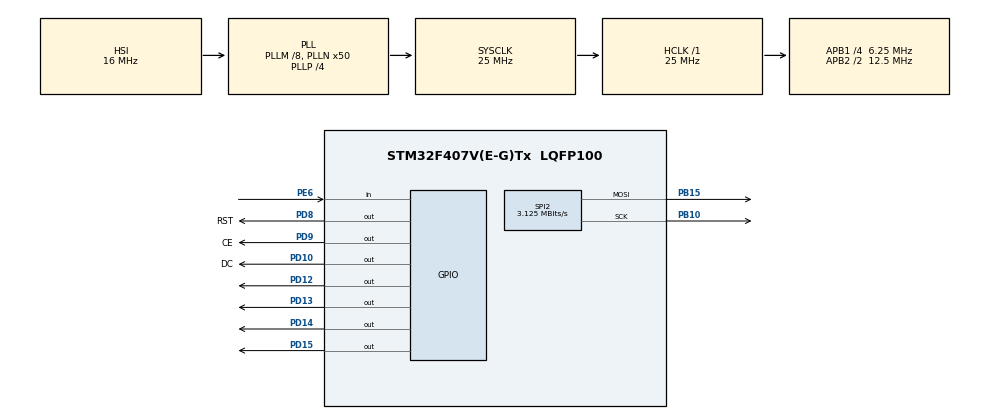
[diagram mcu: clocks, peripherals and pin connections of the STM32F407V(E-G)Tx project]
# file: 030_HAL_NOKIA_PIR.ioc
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Dma.Request0=SPI2_TX
Dma.SPI2_TX.0.Direction=DMA_MEMORY_TO_PERIPH
Dma.SPI2_TX.0.FIFOMode=DMA_FIFOMODE_DISABLE
Dma.SPI2_TX.0.Instance=DMA1_Stream4
Dma.SPI2_TX.0.MemDataAlignment=DMA_MDATAALIGN_BYTE
Dma.SPI2_TX.0.MemInc=DMA_MINC_ENABLE
Dma.SPI2_TX.0.Mode=DMA_CIRCULAR
Dma.SPI2_TX.0.PeriphDataAlignment=DMA_PDATAALIGN_BYTE
Dma.SPI2_TX.0.PeriphInc=DMA_PINC_DISABLE
Dma.SPI2_TX.0.Priority=DMA_PRIORITY_LOW
Mcu.Family=STM32F4
Mcu.Name=STM32F407V(E-G)Tx
Mcu.Package=LQFP100
NVIC.DMA1_Stream4_IRQn=true\:0\:0\:false\:false\:true\:false\:true\:true
NVIC.PriorityGroup=NVIC_PRIORITYGROUP_0
PB10.Mode=TX_Only_Simplex_Unidirect_Master
PB10.Signal=SPI2_SCK
PB15.Mode=TX_Only_Simplex_Unidirect_Master
PB15.Signal=SPI2_MOSI
PD10.GPIO_Label=DC
PD10.Signal=GPIO_Output
PD12.Signal=GPIO_Output
PD13.Signal=GPIO_Output
PD14.Signal=GPIO_Output
PD15.Signal=GPIO_Output
PD8.GPIO_Label=RST
PD8.Signal=GPIO_Output
PD9.GPIO_Label=CE
PD9.Signal=GPIO_Output
PE6.Signal=GPIO_Input
ProjectManager.HeapSize=0x200
ProjectManager.StackSize=0x400
ProjectManager.TargetToolchain=STM32CubeIDE
RCC.48MHZClocksFreq_Value=14285714.285714285
RCC.AHBFreq_Value=25000000
RCC.APB1CLKDivider=RCC_HCLK_DIV4
RCC.APB1Freq_Value=6250000
RCC.APB1TimFreq_Value=12500000
RCC.APB2CLKDivider=RCC_HCLK_DIV2
RCC.APB2Freq_Value=12500000
RCC.APB2TimFreq_Value=25000000
RCC.CortexFreq_Value=25000000
RCC.HCLKFreq_Value=25000000
RCC.HSE_VALUE=8000000
RCC.HSI_VALUE=16000000
RCC.LSE_VALUE=32768
RCC.PLLM=8
RCC.PLLN=50
RCC.PLLP=RCC_PLLP_DIV4
RCC.PLLQ=7
RCC.SYSCLKFreq_VALUE=25000000
RCC.SYSCLKSource=RCC_SYSCLKSOURCE_PLLCLK
RCC.VCOOutputFreq_Value=100000000
SPI2.CalculateBaudRate=3.125 MBits/s
SPI2.Direction=SPI_DIRECTION_2LINES
SPI2.Mode=SPI_MODE_MASTER
SPI2.VirtualType=VM_MASTER
board=STM32F407G-DISC1

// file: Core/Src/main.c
/* USER CODE BEGIN Header */
/**
  ******************************************************************************
  * @file           : main.c
  * @brief          : Main program body
  ******************************************************************************
  * @attention
  *
  * Copyright (c) 2023 STMicroelectronics.
  * All rights reserved.
  *
  * This software is licensed under terms that can be found in the LICENSE file
  * in the root directory of this software component.
  * If no LICENSE file comes with this software, it is provided AS-IS.
  *
  ******************************************************************************
  */
/* USER CODE END Header */
#include "main.h"

/* USER CODE BEGIN Includes */
#include "nokia5110.h"
/* USER CODE END Includes */

SPI_HandleTypeDef hspi2;
DMA_HandleTypeDef hdma_spi2_tx;

/* USER CODE BEGIN PV */
uint8_t frameBuff[504];
/* USER CODE END PV */

void SystemClock_Config(void);
static void MX_GPIO_Init(void);
static void MX_DMA_Init(void);
static void MX_SPI2_Init(void);

int main(void)
{

  /* MCU Configuration--------------------------------------------------------*/

  /* Reset of all peripherals, Initializes the Flash interface and the Systick. */
  HAL_Init();

  /* Configure the system clock */
  SystemClock_Config();

  /* Initialize all configured peripherals */
  MX_GPIO_Init();
  MX_DMA_Init();
  MX_SPI2_Init();
  /* USER CODE BEGIN 2 */
  HAL_GPIO_WritePin(GPIOD, GPIO_PIN_15, GPIO_PIN_SET);
  nokia5110_Init();
  nokia5110_Clear();
  /* USER CODE END 2 */

  /* Infinite loop */
  while (1)
  {

    /* USER CODE BEGIN 3 */
	  if(HAL_GPIO_ReadPin(GPIOE, GPIO_PIN_6) == )
	  {
		  HAL_GPIO_WritePin(GPIOD, GPIO_PIN_12 | GPIO_PIN_13 | GPIO_PIN_14 | GPIO_PIN_15, GPIO_PIN_SET);
	  }
	  else
	  {
		  HAL_GPIO_WritePin(GPIOD, GPIO_PIN_12 | GPIO_PIN_13 | GPIO_PIN_14 | GPIO_PIN_15, GPIO_PIN_RESET);
	  }

  }
  /* USER CODE END 3 */
}

void SystemClock_Config(void)
{
  RCC_OscInitTypeDef RCC_OscInitStruct = {0};
  RCC_ClkInitTypeDef RCC_ClkInitStruct = {0};

  /** Configure the main internal regulator output voltage
  */
  __HAL_RCC_PWR_CLK_ENABLE();
  __HAL_PWR_VOLTAGESCALING_CONFIG(PWR_REGULATOR_VOLTAGE_SCALE1);

  /** Initializes the RCC Oscillators according to the specified parameters
  * in the RCC_OscInitTypeDef structure.
  */
  RCC_OscInitStruct.OscillatorType = RCC_OSCILLATORTYPE_HSI;
  RCC_OscInitStruct.HSIState = RCC_HSI_ON;
  RCC_OscInitStruct.HSICalibrationValue = RCC_HSICALIBRATION_DEFAULT;
  RCC_OscInitStruct.PLL.PLLState = RCC_PLL_ON;
  RCC_OscInitStruct.PLL.PLLSource = RCC_PLLSOURCE_HSI;
  RCC_OscInitStruct.PLL.PLLM = 8;
  RCC_OscInitStruct.PLL.PLLN = 50;
  RCC_OscInitStruct.PLL.PLLP = RCC_PLLP_DIV4;
  RCC_OscInitStruct.PLL.PLLQ = 7;
  if (HAL_RCC_OscConfig(&RCC_OscInitStruct) != HAL_OK)
  {
    Error_Handler();
  }

  /** Initializes the CPU, AHB and APB buses clocks
  */
  RCC_ClkInitStruct.ClockType = RCC_CLOCKTYPE_HCLK|RCC_CLOCKTYPE_SYSCLK
                              |RCC_CLOCKTYPE_PCLK1|RCC_CLOCKTYPE_PCLK2;
  RCC_ClkInitStruct.SYSCLKSource = RCC_SYSCLKSOURCE_PLLCLK;
  RCC_ClkInitStruct.AHBCLKDivider = RCC_SYSCLK_DIV1;
  RCC_ClkInitStruct.APB1CLKDivider = RCC_HCLK_DIV4;
  RCC_ClkInitStruct.APB2CLKDivider = RCC_HCLK_DIV2;

  if (HAL_RCC_ClockConfig(&RCC_ClkInitStruct, FLASH_LATENCY_0) != HAL_OK)
  {
    Error_Handler();
  }
}

static void MX_SPI2_Init(void)
{

  /* SPI2 parameter configuration*/
  hspi2.Instance = SPI2;
  hspi2.Init.Mode = SPI_MODE_MASTER;
  hspi2.Init.Direction = SPI_DIRECTION_2LINES;
  hspi2.Init.DataSize = SPI_DATASIZE_8BIT;
  hspi2.Init.CLKPolarity = SPI_POLARITY_LOW;
  hspi2.Init.CLKPhase = SPI_PHASE_1EDGE;
  hspi2.Init.NSS = SPI_NSS_SOFT;
  hspi2.Init.BaudRatePrescaler = SPI_BAUDRATEPRESCALER_2;
  hspi2.Init.FirstBit = SPI_FIRSTBIT_MSB;
  hspi2.Init.TIMode = SPI_TIMODE_DISABLE;
  hspi2.Init.CRCCalculation = SPI_CRCCALCULATION_DISABLE;
  hspi2.Init.CRCPolynomial = 10;
  if (HAL_SPI_Init(&hspi2) != HAL_OK)
  {
    Error_Handler();
  }

}

static void MX_DMA_Init(void)
{

  /* DMA controller clock enable */
  __HAL_RCC_DMA1_CLK_ENABLE();

  /* DMA interrupt init */
  /* DMA1_Stream4_IRQn interrupt configuration */
  HAL_NVIC_SetPriority(DMA1_Stream4_IRQn, 0, 0);
  HAL_NVIC_EnableIRQ(DMA1_Stream4_IRQn);

}

static void MX_GPIO_Init(void)
{
  GPIO_InitTypeDef GPIO_InitStruct = {0};

  /* GPIO Ports Clock Enable */
  __HAL_RCC_GPIOE_CLK_ENABLE();
  __HAL_RCC_GPIOB_CLK_ENABLE();
  __HAL_RCC_GPIOD_CLK_ENABLE();

  /*Configure GPIO pin Output Level */
  HAL_GPIO_WritePin(GPIOD, RST_Pin|CE_Pin|DC_Pin|GPIO_PIN_12
                          |GPIO_PIN_13|GPIO_PIN_14|GPIO_PIN_15, GPIO_PIN_RESET);

  /*Configure GPIO pin : PE6 */
  GPIO_InitStruct.Pin = GPIO_PIN_6;
  GPIO_InitStruct.Mode = GPIO_MODE_INPUT;
  GPIO_InitStruct.Pull = GPIO_NOPULL;
  HAL_GPIO_Init(GPIOE, &GPIO_InitStruct);

  /*Configure GPIO pins : RST_Pin CE_Pin DC_Pin PD12
                           PD13 PD14 PD15 */
  GPIO_InitStruct.Pin = RST_Pin|CE_Pin|DC_Pin|GPIO_PIN_12
                          |GPIO_PIN_13|GPIO_PIN_14|GPIO_PIN_15;
  GPIO_InitStruct.Mode = GPIO_MODE_OUTPUT_PP;
  GPIO_InitStruct.Pull = GPIO_NOPULL;
  GPIO_InitStruct.Speed = GPIO_SPEED_FREQ_LOW;
  HAL_GPIO_Init(GPIOD, &GPIO_InitStruct);

}

void Error_Handler(void)
{
  __disable_irq();
  while (1)
  {
  }
}
